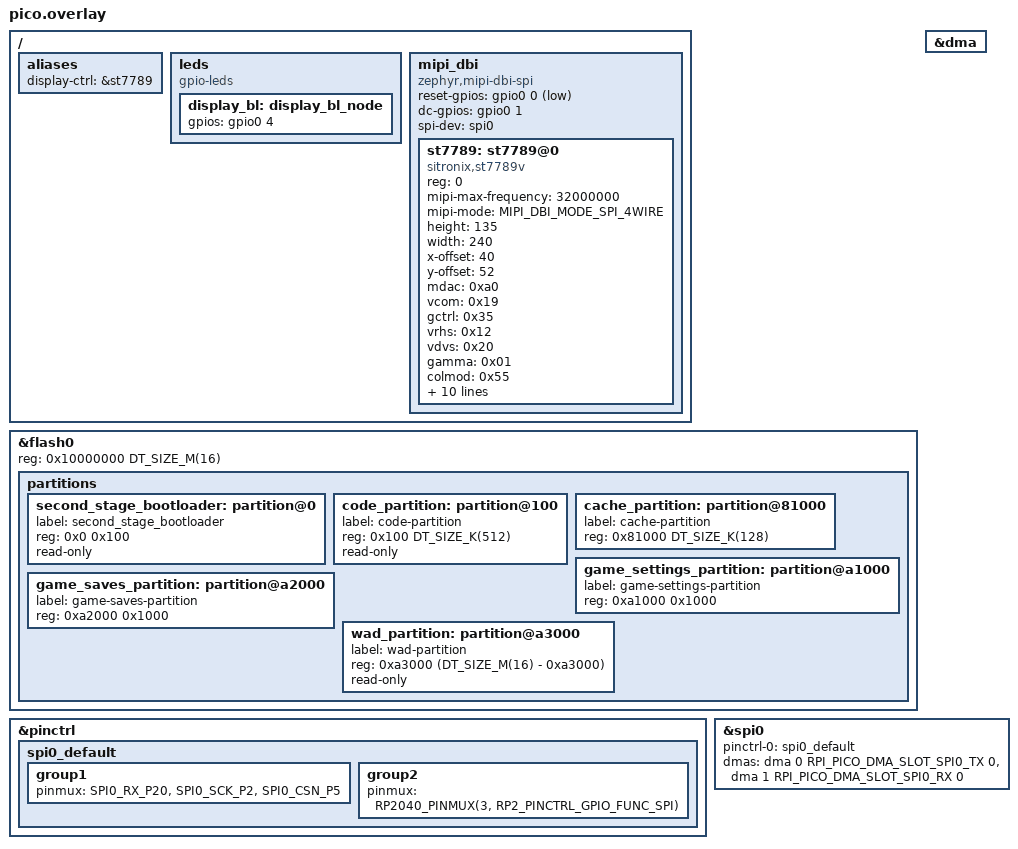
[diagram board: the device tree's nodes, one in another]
#include <zephyr/dt-bindings/mipi_dbi/mipi_dbi.h>
#include <zephyr/dt-bindings/pinctrl/rpi-pico-rp2040-pinctrl.h>
#include <zephyr/dt-bindings/dma/rpi_pico_dma.h>

/{
	aliases 
	{
		display-ctrl = &st7789;
	};

	leds
	{
		compatible = "gpio-leds";
		display_bl: display_bl_node 
		{
			gpios = <&gpio0 4 GPIO_ACTIVE_HIGH>;
		};
	};

	mipi_dbi
	{
		compatible = "zephyr,mipi-dbi-spi";
		reset-gpios = <&gpio0 0 GPIO_ACTIVE_LOW>;
		dc-gpios = <&gpio0 1 GPIO_ACTIVE_HIGH>;
		spi-dev = <&spi0>;
		#address-cells = <1>;
		#size-cells = <0>;

		st7789: st7789@0 
		{
			compatible = "sitronix,st7789v";
			reg = <0>;
			mipi-max-frequency = <32000000>;
			mipi-mode = "MIPI_DBI_MODE_SPI_4WIRE";

			// height = <240>;
			// width = <135>;
			// x-offset = <52>;
			// y-offset = <40>;
			// mdac = <0x00>;

			height = <135>;
			width = <240>;
			x-offset = <40>;
			y-offset = <52>;
			mdac = <0xa0>;

			vcom = <0x19>;
			gctrl = <0x35>;
			vrhs = <0x12>;
			vdvs = <0x20>;
			// inversion-off;
			gamma = <0x01>;
			colmod = <0x55>;
			lcm = <0x2c>;
			porch-param = [ 0c 0c 00 33 33  ];
			cmd2en-param = [ 5a 69 02 01  ];
			pwctrl1-param = [ a4 a1  ];
			pvgam-param = [ D0 04 0D 11 13 2B 3F 54 4C 18 0D 0B 1F 23  ];
			nvgam-param = [ D0 04 0C 11 13 2C 3F 44 51 2F 1F 1F 20 23  ];
			ram-param = [ 00 F8  ];
			rgb-param = [ CD 08 14  ];
		};
	};
};

/delete-node/ &code_partition;
&flash0
{
	reg = <0x10000000 DT_SIZE_M(16)>; //address, size(16MB)

	partitions
	{
		second_stage_bootloader: partition@0 
		{
			label = "second_stage_bootloader";
			reg = < 0x0 0x100 >;
			read-only;
		};
		code_partition: partition@100
		{
			label = "code-partition";
			reg = < 0x100 DT_SIZE_K(512) >;
			read-only;
		};
		cache_partition: partition@81000
		{
			label = "cache-partition";
			reg = < 0x81000 DT_SIZE_K(128) >;
		};
		game_settings_partition: partition@a1000
		{
			label = "game-settings-partition";
			reg = < 0xa1000 0x1000 >;
		};
		game_saves_partition: partition@a2000
		{
			label = "game-saves-partition";
			reg = < 0xa2000 0x1000 >;
		};
		wad_partition: partition@a3000
		{
			label = "wad-partition";
			reg = < 0xa3000 (DT_SIZE_M(16) - 0xa3000) >;
			read-only;
		};
	};
};

&pinctrl
{
	spi0_default: spi0_default 
	{
		group1 
		{
			pinmux = <SPI0_RX_P20>, //miso is not used so put it on some not used pin
			         <SPI0_SCK_P2>,
			         <SPI0_CSN_P5>;
		};
		group2 
		{
			pinmux = <RP2040_PINMUX(3, RP2_PINCTRL_GPIO_FUNC_SPI)>; //mosi
		};
	};
};

&dma  { status = "okay"; };

&spi0
{
	status = "okay";
	pinctrl-0 = <&spi0_default>;
	pinctrl-names = "default";

	//node, channel, slot, priority?
	dmas =  <&dma 0 RPI_PICO_DMA_SLOT_SPI0_TX 0>, 
			<&dma 1 RPI_PICO_DMA_SLOT_SPI0_RX 0>;
 	dma-names = "tx", "rx";
};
